# WS63 register map
File version: 1.0
CPU: other r0p0, little endian, MPU, FPU, 3 interrupt priority bits
Registers are 32-bit, read-write, reset 0x0 unless marked. A register's access mark holds for its fields unless they carry their own. Offsets are from the block's base; [hi:lo] are bit positions; {n}, {i} and the like mark numbered series.

## TIMER — Timer module with 3 independent 32-bit timers (v150)
Base 0x44002000
0x60 ABNOR_INTR_RAW — Abnormal interrupt raw status
  [2:0] abnor_intr_raw ro — Abnormal interrupt raw status for all timers
0x64 ABNOR_IMSK — Abnormal interrupt mask
  [2:0] abnor_imsk — Abnormal interrupt mask for all timers
0x68 ABNOR_INTR_STAT — Abnormal interrupt status
  [2:0] abnor_intr_stat ro — Abnormal interrupt status for all timers
0x78 EOI_REN — End-of-interrupt register
  [2:0] eoi ro — Clear interrupts for all timers (read to clear)
0x7C RAW_INTR_STAT — Raw interrupt status
  [2:0] raw_intr ro — Raw interrupt status for all timers
0x80 INTR_STAT — Interrupt status (masked)
  [2:0] intr_stat ro — Interrupt status for all timers (after mask)
{0x100+0x100*i} TIMER{i}_LOAD_COUNT (i=0..2) — Timer {i} [dim=3] load count
  [31:0] load_count — Timer 0 load count value
{0x108+0x100*i} TIMER{i}_CURRENT_VALUE (i=0..2) — Timer {i} [dim=3] current value
  [31:0] current_value ro — Timer 0 current count value
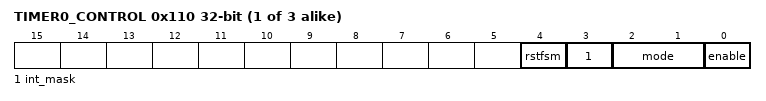
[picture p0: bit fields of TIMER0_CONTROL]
{0x110+0x100*i} TIMER{i}_CONTROL (i=0..2) — Timer {i} [dim=3] control register
  [4] rstfsm wo — Reset FSM: 1=reset timer FSM
  [3] int_mask — Interrupt mask: 0=unmasked; 1=masked
  [2:1] mode — Timer mode: 00=free running; 01=one-shot; 10=periodic
    0=Free-running mode; 1=One-shot mode; 2=Periodic mode
  [0] enable — Timer enable: 0=disabled; 1=enabled
{0x114+0x100*i} TIMER{i}_EOI (i=0..2) — Timer {i} [dim=3] end-of-interrupt
  [0] eoi ro — Read to clear timer 0 interrupt
{0x118+0x100*i} TIMER{i}_RAW_INTR (i=0..2) — Timer {i} [dim=3] raw interrupt status
  [0] raw_intr ro — Raw interrupt status

## WDT — Watchdog timer (v151)
Base 0x40006000
0x00 WDT_LOCK — Watchdog lock register
  [31:0] wdt_lock wo — Write 0x5A5A5A5A to unlock, other values lock
0x04 WDT_LOAD — Watchdog load value
  [31:8] wdt_load — Load count value (24-bit, low 8 bits reserved)
0x08 WDT_RESTART — Watchdog restart register
  [31:0] wdt_restart wo — Write anything except 0x5A5A5A5A to restart counter
0x0C WDT_EOI — Watchdog interrupt clear (read to clear)
  [0] wdt_eoi ro — Read to clear watchdog interrupt
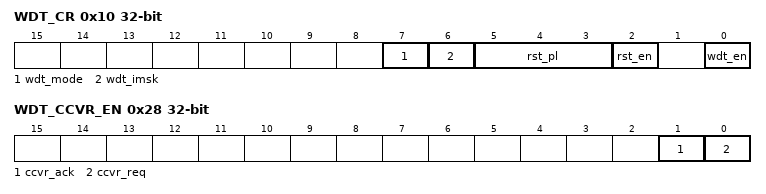
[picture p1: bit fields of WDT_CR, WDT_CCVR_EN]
0x10 WDT_CR — Watchdog control register
  [7] wdt_mode — Mode: 0=one interrupt then reset; 1=two interrupts then reset
    0=Mode1 (Single interrupt then reset); 1=Mode2 (Two interrupts then reset)
  [6] wdt_imsk — Interrupt mask: 0=unmasked; 1=masked
  [5:3] rst_pl — Reset pulse length: 000=2 clocks; up to 111=256 clocks
  [2] rst_en — Reset enable: 0=no reset on timeout; 1=reset on timeout
  [0] wdt_en — Watchdog enable: 0=disabled; 1=enabled
0x14 WDT_CNT — Watchdog current counter value
  [31:0] wdt_cnt ro — Current counter value
0x18 WDT_RAW_INTR — Watchdog raw interrupt status
  [0] wdt_raw_intr ro — Raw interrupt status
0x1C WDT_INTR — Watchdog interrupt status (masked)
  [0] wdt_intr ro — Interrupt status after mask
0x20 WDT_LPIF_STATE — Watchdog low power state
  [2:0] wdt_lpif_state ro — Low power interface state
0x24 WDT_STATUS — Watchdog status
  [0] wdt_status ro — Status: 0=busy; 1=free
0x28 WDT_CCVR_EN — Watchdog counter value request
  [1] ccvr_ack ro — Acknowledge: 1=counter value valid
  [0] ccvr_req wo — Write 1 to request current counter value

## RTC — Real-time clock (48-bit free-running counter, v100)
Base 0x57024000
0x00 RTC_LOAD_COUNT
  [31:0] load_count — Load count value (threshold for interrupt)
0x04 RTC_CURRENT_VALUE — RTC current count value
  [31:0] current_value ro — Current counter value
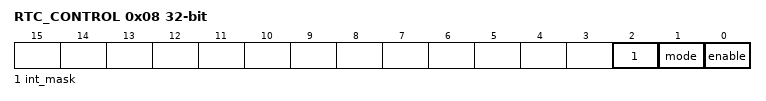
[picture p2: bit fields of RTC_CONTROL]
0x08 RTC_CONTROL
  [2] int_mask — Interrupt mask: 0=unmasked; 1=masked
  [1] mode — Mode: 0=free running; 1=periodic
  [0] enable — RTC enable
0x0C RTC_EOI — RTC end-of-interrupt (read to clear)
  [0] eoi ro — Read to clear RTC interrupt
0x10 RTC_INT_STATUS — RTC interrupt status
  [0] int_status ro — Interrupt status
